AUTOSAR XML (schema 4-2-1)
standard types defined: boolean, float32, uint8, boolean_CompuMethod, boolean_DataConstr, float32_DataConstr, uint8_DataConstr
package /ComponentTypes
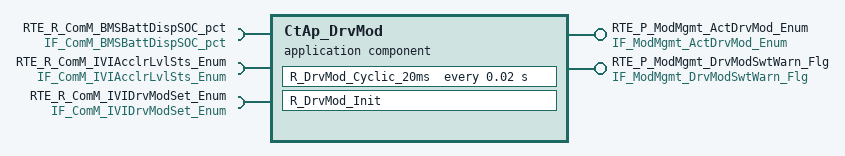
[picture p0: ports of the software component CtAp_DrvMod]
  application sw component type CtAp_DrvMod
    provide port RTE_P_ModMgmt_ActDrvMod_Enum: nonqueued-sender-com-spec{data-element=tec_ModMgmt_ActDrvMod_Enum, init-value=0}, provided-interface=IF_ModMgmt_ActDrvMod_Enum
    provide port RTE_P_ModMgmt_DrvModSwtWarn_Flg: nonqueued-sender-com-spec{data-element=tec_ModMgmt_DrvModSwtWarn_Flg, init-value=0}, provided-interface=IF_ModMgmt_DrvModSwtWarn_Flg
    require port RTE_R_ComM_BMSBattDispSOC_pct: nonqueued-receiver-com-spec{data-element=tec_ComM_BMSBattDispSOC_pct, filter=data-filter-type=ALWAYS, init-value=0}, required-interface=IF_ComM_BMSBattDispSOC_pct
    require port RTE_R_ComM_IVIAcclrLvlSts_Enum: nonqueued-receiver-com-spec{data-element=tec_ComM_IVIAcclrLvlSts_Enum, filter=data-filter-type=ALWAYS, init-value=0}, required-interface=IF_ComM_IVIAcclrLvlSts_Enum
    require port RTE_R_ComM_IVIDrvModSet_Enum: nonqueued-receiver-com-spec{data-element=tec_ComM_IVIDrvModSet_Enum, filter=data-filter-type=ALWAYS, init-value=0}, required-interface=IF_ComM_IVIDrvModSet_Enum
    behavior CtAp_DrvMod_InternalBehavior
      timing event TMT_R_DrvMod_Cyclic_20ms: start-on-event=R_DrvMod_Cyclic_20ms, period=0.02
      init event CtAp_DrvMod_InitEvent: start-on-event=R_DrvMod_Init
      runnable R_DrvMod_Cyclic_20ms
        data-receive-point-by-arguments:
          access REC_RTE_R_ComM_BMSBattDispSOC_pct_tec_ComM_BMSBattDispSOC_pct: accessed-variable=RTE_R_ComM_BMSBattDispSOC_pct.tec_ComM_BMSBattDispSOC_pct
          access REC_RTE_R_ComM_IVIAcclrLvlSts_Enum_tec_ComM_IVIAcclrLvlSts_Enum: accessed-variable=RTE_R_ComM_IVIAcclrLvlSts_Enum.tec_ComM_IVIAcclrLvlSts_Enum
          access REC_RTE_R_ComM_IVIDrvModSet_Enum_tec_ComM_IVIDrvModSet_Enum: accessed-variable=RTE_R_ComM_IVIDrvModSet_Enum.tec_ComM_IVIDrvModSet_Enum
        data-send-points:
          access SEND_RTE_P_ModMgmt_ActDrvMod_Enum_tec_ModMgmt_ActDrvMod_Enum: accessed-variable=RTE_P_ModMgmt_ActDrvMod_Enum.tec_ModMgmt_ActDrvMod_Enum
          access SEND_RTE_P_ModMgmt_DrvModSwtWarn_Flg_tec_ModMgmt_DrvModSwtWarn_Flg: accessed-variable=RTE_P_ModMgmt_DrvModSwtWarn_Flg.tec_ModMgmt_DrvModSwtWarn_Flg
      runnable R_DrvMod_Init
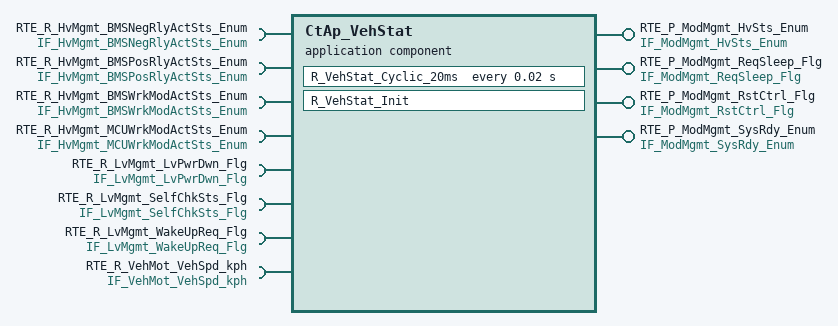
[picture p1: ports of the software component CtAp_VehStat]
  application sw component type CtAp_VehStat
    4 x provide port:
      RTE_P_ModMgmt_HvSts_Enum: nonqueued-sender-com-spec{data-element=tec_ModMgmt_HvSts_Enum, init-value=0}, provided-interface=IF_ModMgmt_HvSts_Enum
      RTE_P_ModMgmt_ReqSleep_Flg: nonqueued-sender-com-spec{data-element=tec_ModMgmt_ReqSleep_Flg, init-value=0}, provided-interface=IF_ModMgmt_ReqSleep_Flg
      RTE_P_ModMgmt_RstCtrl_Flg: nonqueued-sender-com-spec{data-element=tec_ModMgmt_RstCtrl_Flg, init-value=0}, provided-interface=IF_ModMgmt_RstCtrl_Flg
      RTE_P_ModMgmt_SysRdy_Enum: nonqueued-sender-com-spec{data-element=tec_ModMgmt_SysRdy_Enum, init-value=0}, provided-interface=IF_ModMgmt_SysRdy_Enum
    8 x require port:
      RTE_R_HvMgmt_BMSNegRlyActSts_Enum: nonqueued-receiver-com-spec{data-element=tec_HvMgmt_BMSNegRlyActSts_Enum, filter=data-filter-type=ALWAYS, init-value=0}, required-interface=IF_HvMgmt_BMSNegRlyActSts_Enum
      RTE_R_HvMgmt_BMSPosRlyActSts_Enum: nonqueued-receiver-com-spec{data-element=tec_HvMgmt_BMSPosRlyActSts_Enum, filter=data-filter-type=ALWAYS, init-value=0}, required-interface=IF_HvMgmt_BMSPosRlyActSts_Enum
      RTE_R_HvMgmt_BMSWrkModActSts_Enum: nonqueued-receiver-com-spec{data-element=tec_HvMgmt_BMSWrkModActSts_Enum, filter=data-filter-type=ALWAYS, init-value=0}, required-interface=IF_HvMgmt_BMSWrkModActSts_Enum
      RTE_R_HvMgmt_MCUWrkModActSts_Enum: nonqueued-receiver-com-spec{data-element=tec_HvMgmt_MCUWrkModActSts_Enum, filter=data-filter-type=ALWAYS, init-value=0}, required-interface=IF_HvMgmt_MCUWrkModActSts_Enum
      RTE_R_LvMgmt_LvPwrDwn_Flg: nonqueued-receiver-com-spec{data-element=tec_LvMgmt_LvPwrDwn_Flg, filter=data-filter-type=ALWAYS, init-value=0}, required-interface=IF_LvMgmt_LvPwrDwn_Flg
      RTE_R_LvMgmt_SelfChkSts_Flg: nonqueued-receiver-com-spec{data-element=tec_LvMgmt_SelfChkSts_Flg, filter=data-filter-type=ALWAYS, init-value=0}, required-interface=IF_LvMgmt_SelfChkSts_Flg
      RTE_R_LvMgmt_WakeUpReq_Flg: nonqueued-receiver-com-spec{data-element=tec_LvMgmt_WakeUpReq_Flg, filter=data-filter-type=ALWAYS, init-value=0}, required-interface=IF_LvMgmt_WakeUpReq_Flg
      RTE_R_VehMot_VehSpd_kph: nonqueued-receiver-com-spec{data-element=tec_VehMot_VehSpd_kph, filter=data-filter-type=ALWAYS, init-value=0}, required-interface=IF_VehMot_VehSpd_kph
    behavior CtAp_VehStat_InternalBehavior
      timing event TMT_R_VehStat_Cyclic_20ms: start-on-event=R_VehStat_Cyclic_20ms, period=0.02
      init event CtAp_VehStat_InitEvent: start-on-event=R_VehStat_Init
      runnable R_VehStat_Cyclic_20ms
        data-receive-point-by-arguments:
          8 x access:
            REC_RTE_R_HvMgmt_BMSNegRlyActSts_Enum_tec_HvMgmt_BMSNegRlyActSts_Enum: accessed-variable=RTE_R_HvMgmt_BMSNegRlyActSts_Enum.tec_HvMgmt_BMSNegRlyActSts_Enum
            REC_RTE_R_HvMgmt_BMSPosRlyActSts_Enum_tec_HvMgmt_BMSPosRlyActSts_Enum: accessed-variable=RTE_R_HvMgmt_BMSPosRlyActSts_Enum.tec_HvMgmt_BMSPosRlyActSts_Enum
            REC_RTE_R_HvMgmt_BMSWrkModActSts_Enum_tec_HvMgmt_BMSWrkModActSts_Enum: accessed-variable=RTE_R_HvMgmt_BMSWrkModActSts_Enum.tec_HvMgmt_BMSWrkModActSts_Enum
            REC_RTE_R_HvMgmt_MCUWrkModActSts_Enum_tec_HvMgmt_MCUWrkModActSts_Enum: accessed-variable=RTE_R_HvMgmt_MCUWrkModActSts_Enum.tec_HvMgmt_MCUWrkModActSts_Enum
            REC_RTE_R_LvMgmt_LvPwrDwn_Flg_tec_LvMgmt_LvPwrDwn_Flg: accessed-variable=RTE_R_LvMgmt_LvPwrDwn_Flg.tec_LvMgmt_LvPwrDwn_Flg
            REC_RTE_R_LvMgmt_SelfChkSts_Flg_tec_LvMgmt_SelfChkSts_Flg: accessed-variable=RTE_R_LvMgmt_SelfChkSts_Flg.tec_LvMgmt_SelfChkSts_Flg
            REC_RTE_R_LvMgmt_WakeUpReq_Flg_tec_LvMgmt_WakeUpReq_Flg: accessed-variable=RTE_R_LvMgmt_WakeUpReq_Flg.tec_LvMgmt_WakeUpReq_Flg
            REC_RTE_R_VehMot_VehSpd_kph_tec_VehMot_VehSpd_kph: accessed-variable=RTE_R_VehMot_VehSpd_kph.tec_VehMot_VehSpd_kph
        data-send-points:
          4 x access:
            SEND_RTE_P_ModMgmt_HvSts_Enum_tec_ModMgmt_HvSts_Enum: accessed-variable=RTE_P_ModMgmt_HvSts_Enum.tec_ModMgmt_HvSts_Enum
            SEND_RTE_P_ModMgmt_ReqSleep_Flg_tec_ModMgmt_ReqSleep_Flg: accessed-variable=RTE_P_ModMgmt_ReqSleep_Flg.tec_ModMgmt_ReqSleep_Flg
            SEND_RTE_P_ModMgmt_RstCtrl_Flg_tec_ModMgmt_RstCtrl_Flg: accessed-variable=RTE_P_ModMgmt_RstCtrl_Flg.tec_ModMgmt_RstCtrl_Flg
            SEND_RTE_P_ModMgmt_SysRdy_Enum_tec_ModMgmt_SysRdy_Enum: accessed-variable=RTE_P_ModMgmt_SysRdy_Enum.tec_ModMgmt_SysRdy_Enum
      runnable R_VehStat_Init
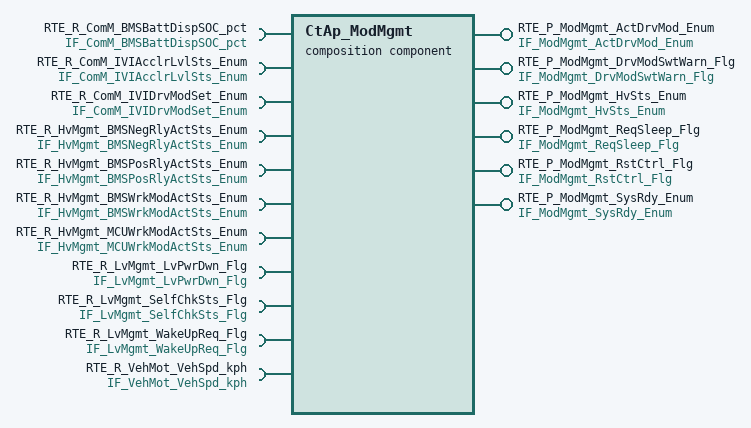
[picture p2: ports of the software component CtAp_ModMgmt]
  composition sw component type CtAp_ModMgmt
    6 x provide port:
      RTE_P_ModMgmt_ActDrvMod_Enum: nonqueued-sender-com-spec{data-element=tec_ModMgmt_ActDrvMod_Enum, init-value=0}, provided-interface=IF_ModMgmt_ActDrvMod_Enum
      RTE_P_ModMgmt_DrvModSwtWarn_Flg: nonqueued-sender-com-spec{data-element=tec_ModMgmt_DrvModSwtWarn_Flg, init-value=0}, provided-interface=IF_ModMgmt_DrvModSwtWarn_Flg
      RTE_P_ModMgmt_HvSts_Enum: nonqueued-sender-com-spec{data-element=tec_ModMgmt_HvSts_Enum, init-value=0}, provided-interface=IF_ModMgmt_HvSts_Enum
      RTE_P_ModMgmt_ReqSleep_Flg: nonqueued-sender-com-spec{data-element=tec_ModMgmt_ReqSleep_Flg, init-value=0}, provided-interface=IF_ModMgmt_ReqSleep_Flg
      RTE_P_ModMgmt_RstCtrl_Flg: nonqueued-sender-com-spec{data-element=tec_ModMgmt_RstCtrl_Flg, init-value=0}, provided-interface=IF_ModMgmt_RstCtrl_Flg
      RTE_P_ModMgmt_SysRdy_Enum: nonqueued-sender-com-spec{data-element=tec_ModMgmt_SysRdy_Enum, init-value=0}, provided-interface=IF_ModMgmt_SysRdy_Enum
    11 x require port:
      RTE_R_ComM_BMSBattDispSOC_pct: nonqueued-receiver-com-spec{data-element=tec_ComM_BMSBattDispSOC_pct, filter=data-filter-type=ALWAYS, init-value=0}, required-interface=IF_ComM_BMSBattDispSOC_pct
      RTE_R_ComM_IVIAcclrLvlSts_Enum: nonqueued-receiver-com-spec{data-element=tec_ComM_IVIAcclrLvlSts_Enum, filter=data-filter-type=ALWAYS, init-value=0}, required-interface=IF_ComM_IVIAcclrLvlSts_Enum
      RTE_R_ComM_IVIDrvModSet_Enum: nonqueued-receiver-com-spec{data-element=tec_ComM_IVIDrvModSet_Enum, filter=data-filter-type=ALWAYS, init-value=0}, required-interface=IF_ComM_IVIDrvModSet_Enum
      RTE_R_HvMgmt_BMSNegRlyActSts_Enum: nonqueued-receiver-com-spec{data-element=tec_HvMgmt_BMSNegRlyActSts_Enum, filter=data-filter-type=ALWAYS, init-value=0}, required-interface=IF_HvMgmt_BMSNegRlyActSts_Enum
      RTE_R_HvMgmt_BMSPosRlyActSts_Enum: nonqueued-receiver-com-spec{data-element=tec_HvMgmt_BMSPosRlyActSts_Enum, filter=data-filter-type=ALWAYS, init-value=0}, required-interface=IF_HvMgmt_BMSPosRlyActSts_Enum
      RTE_R_HvMgmt_BMSWrkModActSts_Enum: nonqueued-receiver-com-spec{data-element=tec_HvMgmt_BMSWrkModActSts_Enum, filter=data-filter-type=ALWAYS, init-value=0}, required-interface=IF_HvMgmt_BMSWrkModActSts_Enum
      RTE_R_HvMgmt_MCUWrkModActSts_Enum: nonqueued-receiver-com-spec{data-element=tec_HvMgmt_MCUWrkModActSts_Enum, filter=data-filter-type=ALWAYS, init-value=0}, required-interface=IF_HvMgmt_MCUWrkModActSts_Enum
      RTE_R_LvMgmt_LvPwrDwn_Flg: nonqueued-receiver-com-spec{data-element=tec_LvMgmt_LvPwrDwn_Flg, filter=data-filter-type=ALWAYS, init-value=0}, required-interface=IF_LvMgmt_LvPwrDwn_Flg
      RTE_R_LvMgmt_SelfChkSts_Flg: nonqueued-receiver-com-spec{data-element=tec_LvMgmt_SelfChkSts_Flg, filter=data-filter-type=ALWAYS, init-value=0}, required-interface=IF_LvMgmt_SelfChkSts_Flg
      RTE_R_LvMgmt_WakeUpReq_Flg: nonqueued-receiver-com-spec{data-element=tec_LvMgmt_WakeUpReq_Flg, filter=data-filter-type=ALWAYS, init-value=0}, required-interface=IF_LvMgmt_WakeUpReq_Flg
      RTE_R_VehMot_VehSpd_kph: nonqueued-receiver-com-spec{data-element=tec_VehMot_VehSpd_kph, filter=data-filter-type=ALWAYS, init-value=0}, required-interface=IF_VehMot_VehSpd_kph
    component CtAp_DrvMod: type=CtAp_DrvMod
    component CtAp_VehStat: type=CtAp_VehStat
    delegate CtAp_DrvMod.RTE_P_ModMgmt_ActDrvMod_Enum <-> outer port CtAp_ModMgmt/RTE_P_ModMgmt_ActDrvMod_Enum
    delegate CtAp_DrvMod.RTE_P_ModMgmt_DrvModSwtWarn_Flg <-> outer port CtAp_ModMgmt/RTE_P_ModMgmt_DrvModSwtWarn_Flg
    delegate CtAp_VehStat.RTE_P_ModMgmt_HvSts_Enum <-> outer port CtAp_ModMgmt/RTE_P_ModMgmt_HvSts_Enum
    delegate CtAp_VehStat.RTE_P_ModMgmt_ReqSleep_Flg <-> outer port CtAp_ModMgmt/RTE_P_ModMgmt_ReqSleep_Flg
    delegate CtAp_VehStat.RTE_P_ModMgmt_RstCtrl_Flg <-> outer port CtAp_ModMgmt/RTE_P_ModMgmt_RstCtrl_Flg
    delegate CtAp_VehStat.RTE_P_ModMgmt_SysRdy_Enum <-> outer port CtAp_ModMgmt/RTE_P_ModMgmt_SysRdy_Enum
    delegate CtAp_DrvMod.RTE_R_ComM_BMSBattDispSOC_pct <-> outer port CtAp_ModMgmt/RTE_R_ComM_BMSBattDispSOC_pct
    delegate CtAp_DrvMod.RTE_R_ComM_IVIAcclrLvlSts_Enum <-> outer port CtAp_ModMgmt/RTE_R_ComM_IVIAcclrLvlSts_Enum
    delegate CtAp_DrvMod.RTE_R_ComM_IVIDrvModSet_Enum <-> outer port CtAp_ModMgmt/RTE_R_ComM_IVIDrvModSet_Enum
    delegate CtAp_VehStat.RTE_R_HvMgmt_BMSNegRlyActSts_Enum <-> outer port CtAp_ModMgmt/RTE_R_HvMgmt_BMSNegRlyActSts_Enum
    delegate CtAp_VehStat.RTE_R_HvMgmt_BMSPosRlyActSts_Enum <-> outer port CtAp_ModMgmt/RTE_R_HvMgmt_BMSPosRlyActSts_Enum
    delegate CtAp_VehStat.RTE_R_HvMgmt_BMSWrkModActSts_Enum <-> outer port CtAp_ModMgmt/RTE_R_HvMgmt_BMSWrkModActSts_Enum
    delegate CtAp_VehStat.RTE_R_HvMgmt_MCUWrkModActSts_Enum <-> outer port CtAp_ModMgmt/RTE_R_HvMgmt_MCUWrkModActSts_Enum
    delegate CtAp_VehStat.RTE_R_LvMgmt_LvPwrDwn_Flg <-> outer port CtAp_ModMgmt/RTE_R_LvMgmt_LvPwrDwn_Flg
    delegate CtAp_VehStat.RTE_R_LvMgmt_SelfChkSts_Flg <-> outer port CtAp_ModMgmt/RTE_R_LvMgmt_SelfChkSts_Flg
    delegate CtAp_VehStat.RTE_R_LvMgmt_WakeUpReq_Flg <-> outer port CtAp_ModMgmt/RTE_R_LvMgmt_WakeUpReq_Flg
    delegate CtAp_VehStat.RTE_R_VehMot_VehSpd_kph <-> outer port CtAp_ModMgmt/RTE_R_VehMot_VehSpd_kph
  swc implementation CtAp_DrvMod_Implementation: behavior=CtAp_DrvMod_InternalBehavior
    code-descriptors:
      code Default: artifact-descriptors=autosar-engineering-object={short-label=Default, category=SWOBJ}
  swc implementation CtAp_VehStat_Implementation: behavior=CtAp_VehStat_InternalBehavior
    code-descriptors:
      code Default: artifact-descriptors=autosar-engineering-object={short-label=Default, category=SWOBJ}
package /PortInterfaces
  17 x sender receiver interface:
    IF_ComM_BMSBattDispSOC_pct: invalidation-policy{data-element=tec_ComM_BMSBattDispSOC_pct, handle-invalid=DONT-INVALIDATE}
      data tec_ComM_BMSBattDispSOC_pct: type=float32
    IF_ComM_IVIAcclrLvlSts_Enum: invalidation-policy{data-element=tec_ComM_IVIAcclrLvlSts_Enum, handle-invalid=DONT-INVALIDATE}
      data tec_ComM_IVIAcclrLvlSts_Enum: type=uint8
    IF_ComM_IVIDrvModSet_Enum: invalidation-policy{data-element=tec_ComM_IVIDrvModSet_Enum, handle-invalid=DONT-INVALIDATE}
      data tec_ComM_IVIDrvModSet_Enum: type=uint8
    IF_HvMgmt_BMSNegRlyActSts_Enum: invalidation-policy{data-element=tec_HvMgmt_BMSNegRlyActSts_Enum, handle-invalid=DONT-INVALIDATE}
      data tec_HvMgmt_BMSNegRlyActSts_Enum: type=uint8
    IF_HvMgmt_BMSPosRlyActSts_Enum: invalidation-policy{data-element=tec_HvMgmt_BMSPosRlyActSts_Enum, handle-invalid=DONT-INVALIDATE}
      data tec_HvMgmt_BMSPosRlyActSts_Enum: type=uint8
    IF_HvMgmt_BMSWrkModActSts_Enum: invalidation-policy{data-element=tec_HvMgmt_BMSWrkModActSts_Enum, handle-invalid=DONT-INVALIDATE}
      data tec_HvMgmt_BMSWrkModActSts_Enum: type=uint8
    IF_HvMgmt_MCUWrkModActSts_Enum: invalidation-policy{data-element=tec_HvMgmt_MCUWrkModActSts_Enum, handle-invalid=DONT-INVALIDATE}
      data tec_HvMgmt_MCUWrkModActSts_Enum: type=uint8
    IF_LvMgmt_LvPwrDwn_Flg: invalidation-policy{data-element=tec_LvMgmt_LvPwrDwn_Flg, handle-invalid=DONT-INVALIDATE}
      data tec_LvMgmt_LvPwrDwn_Flg: type=boolean
    IF_LvMgmt_SelfChkSts_Flg: invalidation-policy{data-element=tec_LvMgmt_SelfChkSts_Flg, handle-invalid=DONT-INVALIDATE}
      data tec_LvMgmt_SelfChkSts_Flg: type=boolean
    IF_LvMgmt_WakeUpReq_Flg: invalidation-policy{data-element=tec_LvMgmt_WakeUpReq_Flg, handle-invalid=DONT-INVALIDATE}
      data tec_LvMgmt_WakeUpReq_Flg: type=boolean
    IF_ModMgmt_ActDrvMod_Enum: invalidation-policy{data-element=tec_ModMgmt_ActDrvMod_Enum, handle-invalid=DONT-INVALIDATE}
      data tec_ModMgmt_ActDrvMod_Enum: type=uint8
    IF_ModMgmt_DrvModSwtWarn_Flg: invalidation-policy{data-element=tec_ModMgmt_DrvModSwtWarn_Flg, handle-invalid=DONT-INVALIDATE}
      data tec_ModMgmt_DrvModSwtWarn_Flg: type=boolean
    IF_ModMgmt_HvSts_Enum: invalidation-policy{data-element=tec_ModMgmt_HvSts_Enum, handle-invalid=DONT-INVALIDATE}
      data tec_ModMgmt_HvSts_Enum: type=uint8
    IF_ModMgmt_ReqSleep_Flg: invalidation-policy{data-element=tec_ModMgmt_ReqSleep_Flg, handle-invalid=DONT-INVALIDATE}
      data tec_ModMgmt_ReqSleep_Flg: type=boolean
    IF_ModMgmt_RstCtrl_Flg: invalidation-policy{data-element=tec_ModMgmt_RstCtrl_Flg, handle-invalid=DONT-INVALIDATE}
      data tec_ModMgmt_RstCtrl_Flg: type=boolean
    IF_ModMgmt_SysRdy_Enum: invalidation-policy{data-element=tec_ModMgmt_SysRdy_Enum, handle-invalid=DONT-INVALIDATE}
      data tec_ModMgmt_SysRdy_Enum: type=uint8
    IF_VehMot_VehSpd_kph: invalidation-policy{data-element=tec_VehMot_VehSpd_kph, handle-invalid=DONT-INVALIDATE}
      data tec_VehMot_VehSpd_kph: type=float32
